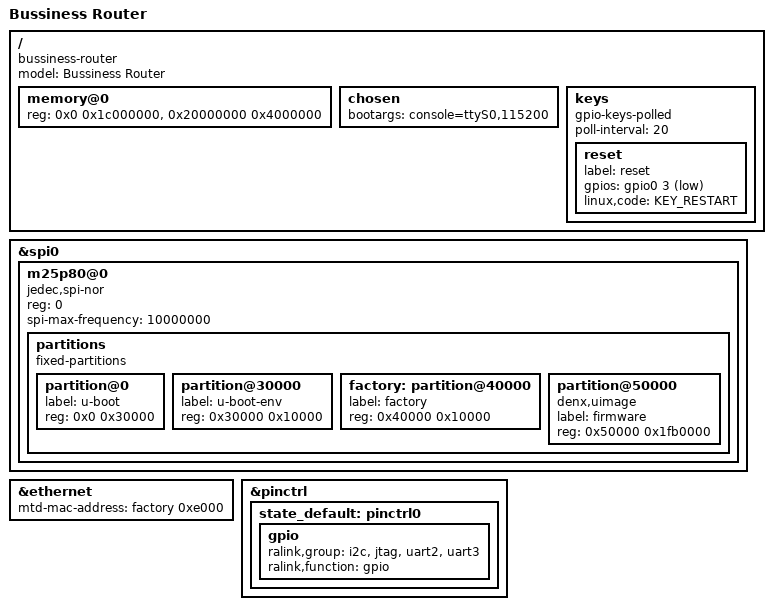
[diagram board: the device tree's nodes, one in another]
/dts-v1/;

#include "mt7621.dtsi"

#include <dt-bindings/gpio/gpio.h>
#include <dt-bindings/input/input.h>

/ {
	compatible = "bussiness-router", "mediatek,mt7621-soc";
	model = "Bussiness Router";

	memory@0 {
		device_type = "memory";
		reg = <0x0 0x1c000000>, <0x20000000 0x4000000>;
	};

	chosen {
		bootargs = "console=ttyS0,115200";
	};

	keys {
		compatible = "gpio-keys-polled";
		poll-interval = <20>;

		reset {
			label = "reset";
			gpios = <&gpio0 3 GPIO_ACTIVE_LOW>;
			linux,code = <KEY_RESTART>;
		};
	};
};

&spi0 {
	status = "okay";

	m25p80@0 {
		compatible = "jedec,spi-nor";
		reg = <0>;
		spi-max-frequency = <10000000>;

		partitions {
			compatible = "fixed-partitions";
			#address-cells = <1>;
			#size-cells = <1>;

			partition@0 {
				label = "u-boot";
				reg = <0x0 0x30000>;
			};

			partition@30000 {
				label = "u-boot-env";
				reg = <0x30000 0x10000>;
			};

			factory: partition@40000 {
				label = "factory";
				reg = <0x40000 0x10000>;
			};

			partition@50000 {
				compatible = "denx,uimage";
				label = "firmware";
				reg = <0x50000 0x1fb0000>;
			};
		};
	};
};

&ethernet {
	mtd-mac-address = <&factory 0xe000>;
};

&pinctrl {
	state_default: pinctrl0 {
		gpio {
			ralink,group = "i2c", "jtag", "uart2", "uart3";
			ralink,function = "gpio";
		};
	};
};
